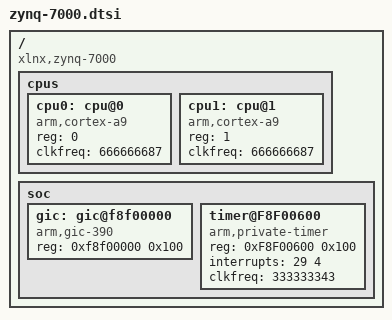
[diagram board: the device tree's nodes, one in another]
// SPDX-License-Identifier: MIT OR Apache-2.0
//
// Copyright (c) 2024 kwangdo.yi<kwangdo.yi@gmail.com>

/*
 * Included for example, not used
 */

/ {
	#address-cells = <1>;
	#size-cells = <1>;
	compatible = "xlnx,zynq-7000";

	cpus {
		#address-cells = <1>;
		#size-cells = <0>;

		cpu0: cpu@0 {
			compatible = "arm,cortex-a9";
			device_type = "cpu";
			reg = <0>;
			clkfreq = <666666687>;
		};

		cpu1: cpu@1 {
			compatible = "arm,cortex-a9";
			device_type = "cpu";
			reg = <1>;
			clkfreq = <666666687>;
		};
	};

	soc {
		gic: gic@f8f00000 {
			compatible = "arm,gic-390";
			reg = <0xf8f00000 0x100>;
		};

		timer@F8F00600 {
			compatible = "arm,private-timer";
			reg = <0xF8F00600 0x100>;
			interrupts = <29 4>;
			clkfreq = <333333343>;
		};
	};
};
